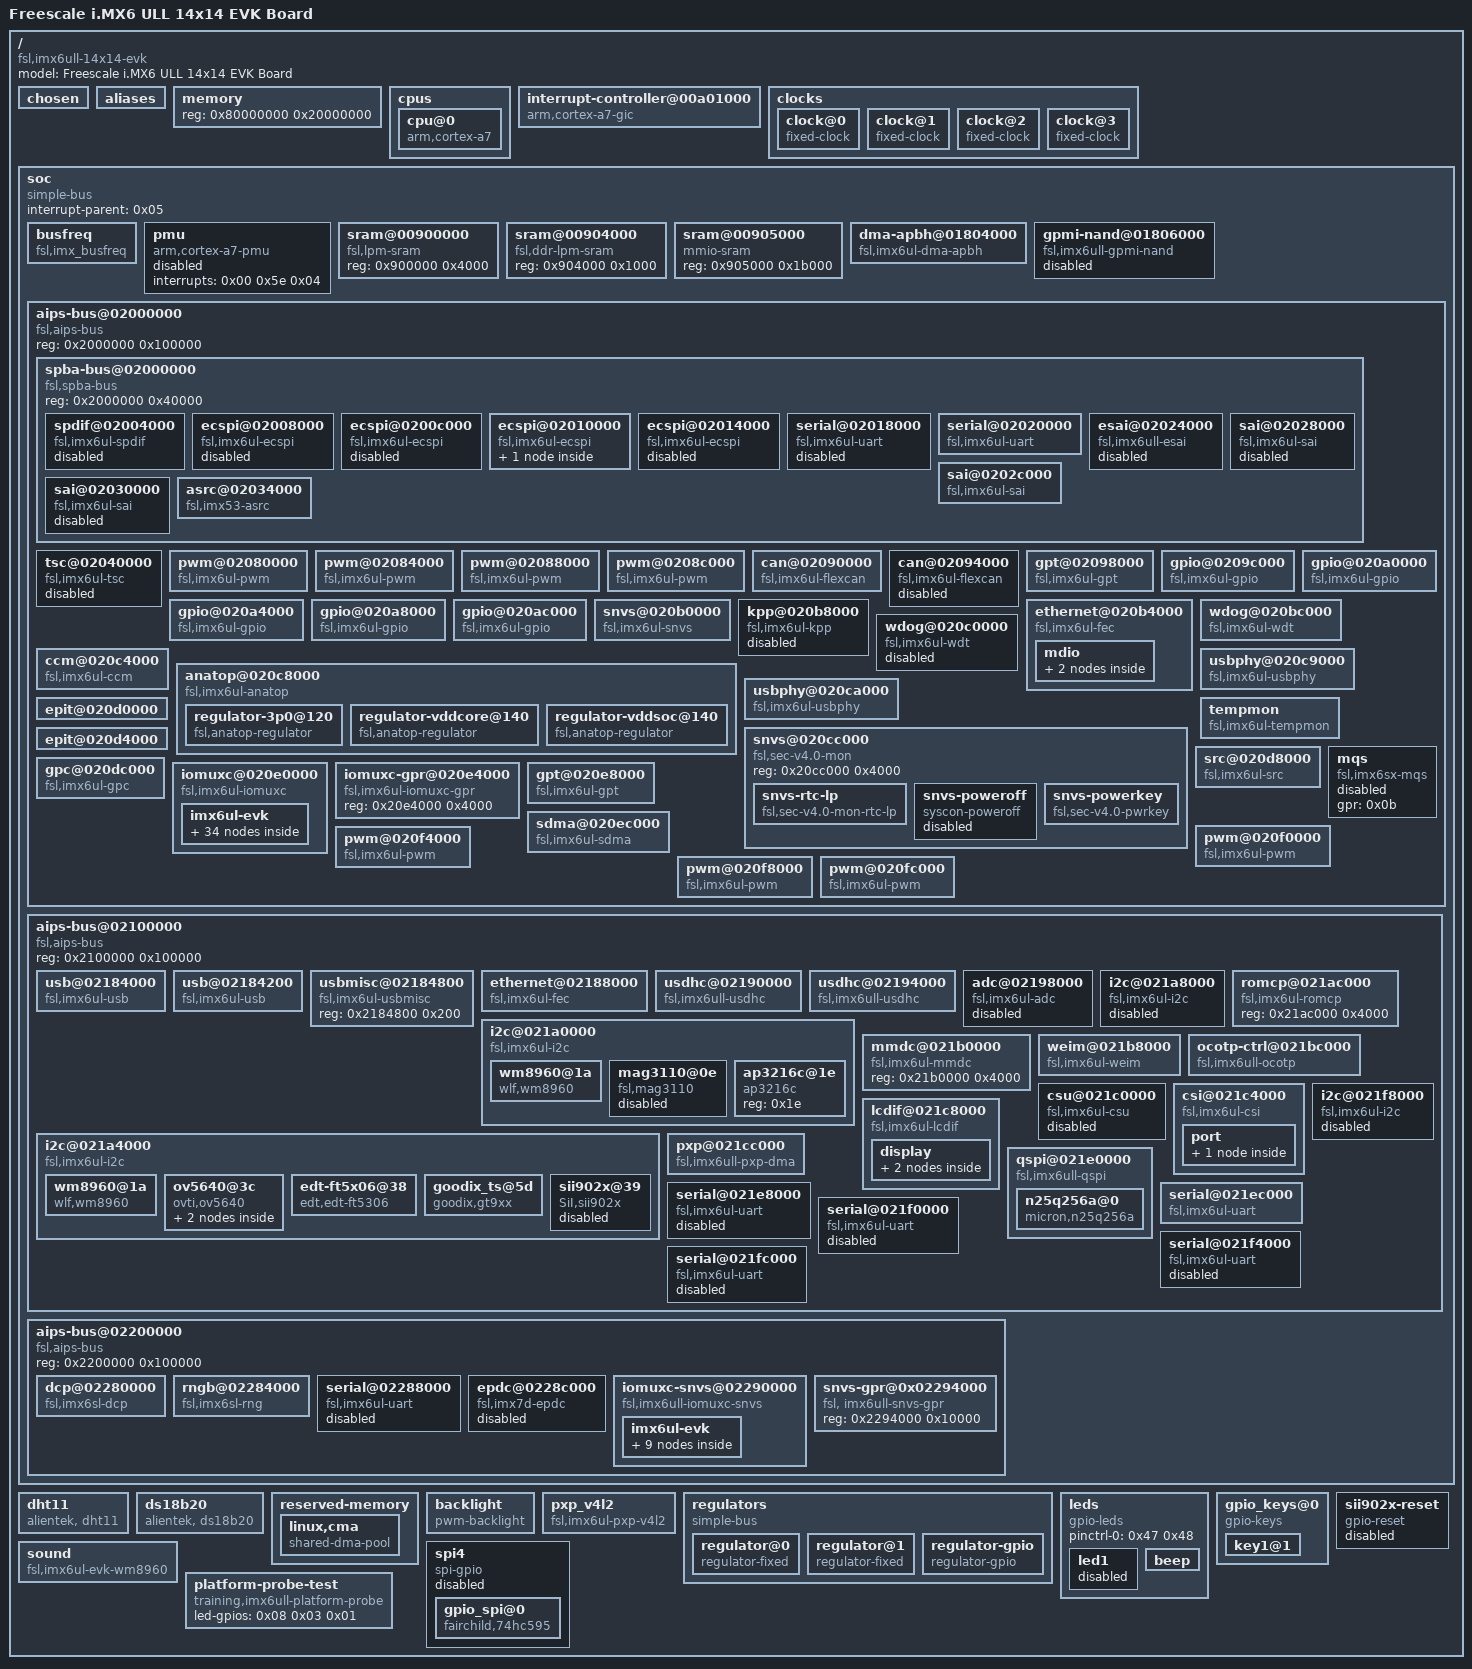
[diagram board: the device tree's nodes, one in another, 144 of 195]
/dts-v1/;

/memreserve/	0x0000000083000000 0x000000000000a000;
/ {
	#address-cells = <0x01>;
	#size-cells = <0x01>;
	model = "Freescale i.MX6 ULL 14x14 EVK Board";
	compatible = "fsl,imx6ull-14x14-evk\0fsl,imx6ull";

	chosen {
		bootargs = "console=ttymxc0,115200 root=/dev/mmcblk1p2 rootwait rw";
		stdout-path = "/soc/aips-bus@02000000/spba-bus@02000000/serial@02020000";
	};

	aliases {
		can0 = "/soc/aips-bus@02000000/can@02090000";
		can1 = "/soc/aips-bus@02000000/can@02094000";
		ethernet0 = "/soc/aips-bus@02100000/ethernet@02188000";
		ethernet1 = "/soc/aips-bus@02000000/ethernet@020b4000";
		gpio0 = "/soc/aips-bus@02000000/gpio@0209c000";
		gpio1 = "/soc/aips-bus@02000000/gpio@020a0000";
		gpio2 = "/soc/aips-bus@02000000/gpio@020a4000";
		gpio3 = "/soc/aips-bus@02000000/gpio@020a8000";
		gpio4 = "/soc/aips-bus@02000000/gpio@020ac000";
		i2c0 = "/soc/aips-bus@02100000/i2c@021a0000";
		i2c1 = "/soc/aips-bus@02100000/i2c@021a4000";
		i2c2 = "/soc/aips-bus@02100000/i2c@021a8000";
		i2c3 = "/soc/aips-bus@02100000/i2c@021f8000";
		mmc0 = "/soc/aips-bus@02100000/usdhc@02190000";
		mmc1 = "/soc/aips-bus@02100000/usdhc@02194000";
		serial0 = "/soc/aips-bus@02000000/spba-bus@02000000/serial@02020000";
		serial1 = "/soc/aips-bus@02100000/serial@021e8000";
		serial2 = "/soc/aips-bus@02100000/serial@021ec000";
		serial3 = "/soc/aips-bus@02100000/serial@021f0000";
		serial4 = "/soc/aips-bus@02100000/serial@021f4000";
		serial5 = "/soc/aips-bus@02100000/serial@021fc000";
		serial6 = "/soc/aips-bus@02000000/spba-bus@02000000/serial@02018000";
		serial7 = "/soc/aips-bus@02200000/serial@02288000";
		spi0 = "/soc/aips-bus@02000000/spba-bus@02000000/ecspi@02008000";
		spi1 = "/soc/aips-bus@02000000/spba-bus@02000000/ecspi@0200c000";
		spi2 = "/soc/aips-bus@02000000/spba-bus@02000000/ecspi@02010000";
		spi3 = "/soc/aips-bus@02000000/spba-bus@02000000/ecspi@02014000";
		usbphy0 = "/soc/aips-bus@02000000/usbphy@020c9000";
		usbphy1 = "/soc/aips-bus@02000000/usbphy@020ca000";
	};

	memory {
		device_type = "memory";
		reg = <0x80000000 0x20000000>;
	};

	cpus {
		#address-cells = <0x01>;
		#size-cells = <0x00>;

		cpu@0 {
			compatible = "arm,cortex-a7";
			device_type = "cpu";
			reg = <0x00>;
			clock-latency = <0xee6c>;
			operating-points = <0xf32a0 0x137478 0xc15c0 0x12b128 0x80e80 0x11edd8 0x60ae0 0xfa3e8 0x30570 0xe7ef0>;
			fsl,soc-operating-points = <0xf32a0 0x11edd8 0xc15c0 0x11edd8 0x80e80 0x11edd8 0x60ae0 0x11edd8 0x30570 0x11edd8>;
			fsl,low-power-run;
			clocks = <0x01 0x5d 0x01 0x1a 0x01 0x26 0x01 0xdb 0x01 0x38 0x01 0x39 0x01 0x19 0x01 0x12 0x01 0x0b 0x01 0x04 0x01 0x03>;
			clock-names = "arm\0pll2_bus\0pll2_pfd2_396m\0secondary_sel\0step\0pll1_sw\0pll1_sys\0pll1_bypass\0pll1\0pll1_bypass_src\0osc";
			arm-supply = <0x02>;
			soc-supply = <0x03>;
			dc-supply = <0x04>;
		};
	};

	interrupt-controller@00a01000 {
		compatible = "arm,cortex-a7-gic";
		#interrupt-cells = <0x03>;
		interrupt-controller;
		reg = <0xa01000 0x1000 0xa02000 0x100>;
		linux,phandle = <0x20>;
		phandle = <0x20>;
	};

	clocks {
		#address-cells = <0x01>;
		#size-cells = <0x00>;

		clock@0 {
			compatible = "fixed-clock";
			reg = <0x00>;
			#clock-cells = <0x00>;
			clock-frequency = <0x8000>;
			clock-output-names = "ckil";
			linux,phandle = <0x18>;
			phandle = <0x18>;
		};

		clock@1 {
			compatible = "fixed-clock";
			reg = <0x01>;
			#clock-cells = <0x00>;
			clock-frequency = <0x16e3600>;
			clock-output-names = "osc";
			linux,phandle = <0x19>;
			phandle = <0x19>;
		};

		clock@2 {
			compatible = "fixed-clock";
			reg = <0x02>;
			#clock-cells = <0x00>;
			clock-frequency = <0x00>;
			clock-output-names = "ipp_di0";
			linux,phandle = <0x1a>;
			phandle = <0x1a>;
		};

		clock@3 {
			compatible = "fixed-clock";
			reg = <0x03>;
			#clock-cells = <0x00>;
			clock-frequency = <0x00>;
			clock-output-names = "ipp_di1";
			linux,phandle = <0x1b>;
			phandle = <0x1b>;
		};
	};

	soc {
		#address-cells = <0x01>;
		#size-cells = <0x01>;
		compatible = "simple-bus";
		interrupt-parent = <0x05>;
		ranges;

		busfreq {
			compatible = "fsl,imx_busfreq";
			clocks = <0x01 0x26 0x01 0x35 0x01 0x1a 0x01 0x5d 0x01 0x1b 0x01 0x55 0x01 0x3c 0x01 0x5e 0x01 0x3e 0x01 0x03 0x01 0x60 0x01 0xd4 0x01 0x56 0x01 0x3d 0x01 0x5f 0x01 0x3f 0x01 0x38 0x01 0xa3 0x01 0x04 0x01 0x12 0x01 0x19 0x01 0x39 0x01 0x0b>;
			clock-names = "pll2_pfd2_396m\0pll2_198m\0pll2_bus\0arm\0pll3_usb_otg\0periph\0periph_pre\0periph_clk2\0periph_clk2_sel\0osc\0ahb\0ocram\0periph2\0periph2_pre\0periph2_clk2\0periph2_clk2_sel\0step\0mmdc\0pll1_bypass_src\0pll1_bypass\0pll1_sys\0pll1_sw\0pll1";
			fsl,max_ddr_freq = <0x17d78400>;
		};

		pmu {
			compatible = "arm,cortex-a7-pmu";
			interrupts = <0x00 0x5e 0x04>;
			status = "disabled";
		};

		sram@00900000 {
			compatible = "fsl,lpm-sram";
			reg = <0x900000 0x4000>;
		};

		sram@00904000 {
			compatible = "fsl,ddr-lpm-sram";
			reg = <0x904000 0x1000>;
		};

		sram@00905000 {
			compatible = "mmio-sram";
			reg = <0x905000 0x1b000>;
			linux,phandle = <0x22>;
			phandle = <0x22>;
		};

		dma-apbh@01804000 {
			compatible = "fsl,imx6ul-dma-apbh\0fsl,imx28-dma-apbh";
			reg = <0x1804000 0x2000>;
			interrupts = <0x00 0x0d 0x04 0x00 0x0d 0x04 0x00 0x0d 0x04 0x00 0x0d 0x04>;
			interrupt-names = "gpmi0\0gpmi1\0gpmi2\0gpmi3";
			#dma-cells = <0x01>;
			dma-channels = <0x04>;
			clocks = <0x01 0x80>;
			linux,phandle = <0x06>;
			phandle = <0x06>;
		};

		gpmi-nand@01806000 {
			compatible = "fsl,imx6ull-gpmi-nand\0fsl, imx6ul-gpmi-nand";
			#address-cells = <0x01>;
			#size-cells = <0x01>;
			reg = <0x1806000 0x2000 0x1808000 0x4000>;
			reg-names = "gpmi-nand\0bch";
			interrupts = <0x00 0x0f 0x04>;
			interrupt-names = "bch";
			clocks = <0x01 0x85 0x01 0x86 0x01 0x84 0x01 0x83 0x01 0xdc>;
			clock-names = "gpmi_io\0gpmi_apb\0gpmi_bch\0gpmi_bch_apb\0per1_bch";
			dmas = <0x06 0x00>;
			dma-names = "rx-tx";
			status = "disabled";
		};

		aips-bus@02000000 {
			compatible = "fsl,aips-bus\0simple-bus";
			#address-cells = <0x01>;
			#size-cells = <0x01>;
			reg = <0x2000000 0x100000>;
			ranges;

			spba-bus@02000000 {
				compatible = "fsl,spba-bus\0simple-bus";
				#address-cells = <0x01>;
				#size-cells = <0x01>;
				reg = <0x2000000 0x40000>;
				ranges;

				spdif@02004000 {
					compatible = "fsl,imx6ul-spdif\0fsl,imx35-spdif";
					reg = <0x2004000 0x4000>;
					interrupts = <0x00 0x34 0x04>;
					dmas = <0x07 0x29 0x12 0x00 0x07 0x2a 0x12 0x00>;
					dma-names = "rx\0tx";
					clocks = <0x01 0xd5 0x01 0x03 0x01 0xbc 0x01 0x00 0x01 0x00 0x01 0x00 0x01 0x64 0x01 0x00 0x01 0x00 0x01 0xbb>;
					clock-names = "core\0rxtx0\0rxtx1\0rxtx2\0rxtx3\0rxtx4\0rxtx5\0rxtx6\0rxtx7\0dma";
					status = "disabled";
				};

				ecspi@02008000 {
					#address-cells = <0x01>;
					#size-cells = <0x00>;
					compatible = "fsl,imx6ul-ecspi\0fsl,imx51-ecspi";
					reg = <0x2008000 0x4000>;
					interrupts = <0x00 0x1f 0x04>;
					clocks = <0x01 0x8b 0x01 0x8b>;
					clock-names = "ipg\0per";
					dmas = <0x07 0x03 0x07 0x01 0x07 0x04 0x07 0x02>;
					dma-names = "rx\0tx";
					status = "disabled";
				};

				ecspi@0200c000 {
					#address-cells = <0x01>;
					#size-cells = <0x00>;
					compatible = "fsl,imx6ul-ecspi\0fsl,imx51-ecspi";
					reg = <0x200c000 0x4000>;
					interrupts = <0x00 0x20 0x04>;
					clocks = <0x01 0x8c 0x01 0x8c>;
					clock-names = "ipg\0per";
					dmas = <0x07 0x05 0x07 0x01 0x07 0x06 0x07 0x02>;
					dma-names = "rx\0tx";
					status = "disabled";
				};

				ecspi@02010000 {
					#address-cells = <0x01>;
					#size-cells = <0x00>;
					compatible = "fsl,imx6ul-ecspi\0fsl,imx51-ecspi";
					reg = <0x2010000 0x4000>;
					interrupts = <0x00 0x21 0x04>;
					clocks = <0x01 0x8d 0x01 0x8d>;
					clock-names = "ipg\0per";
					dmas = <0x07 0x07 0x07 0x01 0x07 0x08 0x07 0x02>;
					dma-names = "rx\0tx";
					status = "okay";
					fsl,spi-num-chipselects = <0x01>;
					cs-gpio = <0x08 0x14 0x01>;
					pinctrl-names = "default";
					pinctrl-0 = <0x09>;

					icm20608@0 {
						compatible = "alientek,icm20608";
						spi-max-frequency = <0x7a1200>;
						reg = <0x00>;
					};
				};

				ecspi@02014000 {
					#address-cells = <0x01>;
					#size-cells = <0x00>;
					compatible = "fsl,imx6ul-ecspi\0fsl,imx51-ecspi";
					reg = <0x2014000 0x4000>;
					interrupts = <0x00 0x22 0x04>;
					clocks = <0x01 0x8e 0x01 0x8e>;
					clock-names = "ipg\0per";
					dmas = <0x07 0x09 0x07 0x01 0x07 0x0a 0x07 0x02>;
					dma-names = "rx\0tx";
					status = "disabled";
				};

				serial@02018000 {
					compatible = "fsl,imx6ul-uart\0fsl,imx6q-uart\0fsl,imx21-uart";
					reg = <0x2018000 0x4000>;
					interrupts = <0x00 0x27 0x04>;
					clocks = <0x01 0xc9 0x01 0xca>;
					clock-names = "ipg\0per";
					dmas = <0x07 0x2b 0x04 0x00 0x07 0x2c 0x04 0x00>;
					dma-names = "rx\0tx";
					status = "disabled";
				};

				serial@02020000 {
					compatible = "fsl,imx6ul-uart\0fsl,imx6q-uart\0fsl,imx21-uart";
					reg = <0x2020000 0x4000>;
					interrupts = <0x00 0x1a 0x04>;
					clocks = <0x01 0xbd 0x01 0xbe>;
					clock-names = "ipg\0per";
					status = "okay";
					pinctrl-names = "default";
					pinctrl-0 = <0x0a>;
				};

				esai@02024000 {
					compatible = "fsl,imx6ull-esai";
					reg = <0x2024000 0x4000>;
					interrupts = <0x00 0x33 0x04>;
					clocks = <0x01 0xe5 0x01 0xe4 0x01 0xe3 0x01 0xe5 0x01 0xbb>;
					clock-names = "core\0mem\0extal\0fsys\0dma";
					dmas = <0x07 0x00 0x15 0x00 0x07 0x2f 0x15 0x00>;
					dma-names = "rx\0tx";
					dma-source = <0x0b 0x00 0x0e 0x00 0x0f>;
					status = "disabled";
				};

				sai@02028000 {
					compatible = "fsl,imx6ul-sai\0fsl,imx6sx-sai";
					reg = <0x2028000 0x4000>;
					interrupts = <0x00 0x61 0x04>;
					clocks = <0x01 0xb3 0x01 0x00 0x01 0xb2 0x01 0x00 0x01 0x00>;
					clock-names = "bus\0mclk0\0mclk1\0mclk2\0mclk3";
					dma-names = "rx\0tx";
					dmas = <0x07 0x23 0x18 0x00 0x07 0x24 0x18 0x00>;
					status = "disabled";
				};

				sai@0202c000 {
					compatible = "fsl,imx6ul-sai\0fsl,imx6sx-sai";
					reg = <0x202c000 0x4000>;
					interrupts = <0x00 0x62 0x04>;
					clocks = <0x01 0xb5 0x01 0x00 0x01 0xb4 0x01 0x00 0x01 0x00>;
					clock-names = "bus\0mclk0\0mclk1\0mclk2\0mclk3";
					dma-names = "rx\0tx";
					dmas = <0x07 0x25 0x18 0x00 0x07 0x26 0x18 0x00>;
					status = "okay";
					pinctrl-names = "default";
					pinctrl-0 = <0x0c 0x0d>;
					assigned-clocks = <0x01 0x47 0x01 0xb4>;
					assigned-clock-parents = <0x01 0x32>;
					assigned-clock-rates = <0x00 0xac4400>;
					linux,phandle = <0x4a>;
					phandle = <0x4a>;
				};

				sai@02030000 {
					compatible = "fsl,imx6ul-sai\0fsl,imx6sx-sai";
					reg = <0x2030000 0x4000>;
					interrupts = <0x00 0x18 0x04>;
					clocks = <0x01 0xb7 0x01 0x00 0x01 0xb6 0x01 0x00 0x01 0x00>;
					clock-names = "bus\0mclk0\0mclk1\0mclk2\0mclk3";
					dma-names = "rx\0tx";
					dmas = <0x07 0x27 0x18 0x00 0x07 0x28 0x18 0x00>;
					status = "disabled";
				};

				asrc@02034000 {
					compatible = "fsl,imx53-asrc";
					reg = <0x2034000 0x4000>;
					interrupts = <0x00 0x32 0x04>;
					clocks = <0x01 0x81 0x01 0x82 0x01 0x00 0x01 0x00 0x01 0x00 0x01 0x00 0x01 0x00 0x01 0x00 0x01 0x00 0x01 0x00 0x01 0x00 0x01 0x00 0x01 0x00 0x01 0x00 0x01 0x00 0x01 0xbc 0x01 0x00 0x01 0x00 0x01 0xbb>;
					clock-names = "mem\0ipg\0asrck_0\0asrck_1\0asrck_2\0asrck_3\0asrck_4\0asrck_5\0asrck_6\0asrck_7\0asrck_8\0asrck_9\0asrck_a\0asrck_b\0asrck_c\0asrck_d\0asrck_e\0asrck_f\0dma";
					dmas = <0x07 0x11 0x17 0x01 0x07 0x12 0x17 0x01 0x07 0x13 0x17 0x01 0x07 0x14 0x17 0x01 0x07 0x15 0x17 0x01 0x07 0x16 0x17 0x01>;
					dma-names = "rxa\0rxb\0rxc\0txa\0txb\0txc";
					fsl,asrc-rate = <0xbb80>;
					fsl,asrc-width = <0x10>;
					status = "okay";
					linux,phandle = <0x4d>;
					phandle = <0x4d>;
				};
			};

			tsc@02040000 {
				compatible = "fsl,imx6ul-tsc";
				reg = <0x2040000 0x4000 0x219c000 0x4000>;
				interrupts = <0x00 0x03 0x04 0x00 0x65 0x04>;
				clocks = <0x01 0x64 0x01 0x7c>;
				clock-names = "tsc\0adc";
				status = "disabled";
				pinctrl-names = "default";
				pinctrl-0 = <0x0e>;
				xnur-gpio = <0x08 0x03 0x01>;
				measure-delay-time = <0xffff>;
				pre-charge-time = <0xfff>;
			};

			pwm@02080000 {
				compatible = "fsl,imx6ul-pwm\0fsl,imx27-pwm";
				reg = <0x2080000 0x4000>;
				interrupts = <0x00 0x53 0x04>;
				clocks = <0x01 0xa7 0x01 0xa7>;
				clock-names = "ipg\0per";
				#pwm-cells = <0x02>;
				pinctrl-names = "default";
				pinctrl-0 = <0x0f>;
				status = "okay";
				linux,phandle = <0x44>;
				phandle = <0x44>;
			};

			pwm@02084000 {
				compatible = "fsl,imx6ul-pwm\0fsl,imx27-pwm";
				reg = <0x2084000 0x4000>;
				interrupts = <0x00 0x54 0x04>;
				clocks = <0x01 0x00 0x01 0x00>;
				clock-names = "ipg\0per";
				#pwm-cells = <0x02>;
			};

			pwm@02088000 {
				compatible = "fsl,imx6ul-pwm\0fsl,imx27-pwm";
				reg = <0x2088000 0x4000>;
				interrupts = <0x00 0x55 0x04>;
				clocks = <0x01 0xa9 0x01 0xa9>;
				clock-names = "ipg\0per";
				#pwm-cells = <0x02>;
			};

			pwm@0208c000 {
				compatible = "fsl,imx6ul-pwm\0fsl,imx27-pwm";
				reg = <0x208c000 0x4000>;
				interrupts = <0x00 0x56 0x04>;
				clocks = <0x01 0x00 0x01 0x00>;
				clock-names = "ipg\0per";
				#pwm-cells = <0x02>;
			};

			can@02090000 {
				compatible = "fsl,imx6ul-flexcan\0fsl,imx6q-flexcan";
				reg = <0x2090000 0x4000>;
				interrupts = <0x00 0x6e 0x04>;
				clocks = <0x01 0x94 0x01 0x95>;
				clock-names = "ipg\0per";
				stop-mode = <0x0b 0x10 0x01 0x10 0x11>;
				status = "okay";
				pinctrl-names = "default";
				pinctrl-0 = <0x10>;
				xceiver-supply = <0x11>;
			};

			can@02094000 {
				compatible = "fsl,imx6ul-flexcan\0fsl,imx6q-flexcan";
				reg = <0x2094000 0x4000>;
				interrupts = <0x00 0x6f 0x04>;
				clocks = <0x01 0x96 0x01 0x97>;
				clock-names = "ipg\0per";
				stop-mode = <0x0b 0x10 0x02 0x10 0x12>;
				status = "disabled";
				pinctrl-names = "default";
				pinctrl-0 = <0x12>;
				xceiver-supply = <0x11>;
			};

			gpt@02098000 {
				compatible = "fsl,imx6ul-gpt\0fsl,imx31-gpt";
				reg = <0x2098000 0x4000>;
				interrupts = <0x00 0x37 0x04>;
				clocks = <0x01 0x98 0x01 0xd6>;
				clock-names = "ipg\0osc_per";
			};

			gpio@0209c000 {
				compatible = "fsl,imx6ul-gpio\0fsl,imx35-gpio";
				reg = <0x209c000 0x4000>;
				interrupts = <0x00 0x42 0x04 0x00 0x43 0x04>;
				gpio-controller;
				#gpio-cells = <0x02>;
				interrupt-controller;
				#interrupt-cells = <0x02>;
				linux,phandle = <0x08>;
				phandle = <0x08>;
			};

			gpio@020a0000 {
				compatible = "fsl,imx6ul-gpio\0fsl,imx35-gpio";
				reg = <0x20a0000 0x4000>;
				interrupts = <0x00 0x44 0x04 0x00 0x45 0x04>;
				gpio-controller;
				#gpio-cells = <0x02>;
				interrupt-controller;
				#interrupt-cells = <0x02>;
			};

			gpio@020a4000 {
				compatible = "fsl,imx6ul-gpio\0fsl,imx35-gpio";
				reg = <0x20a4000 0x4000>;
				interrupts = <0x00 0x46 0x04 0x00 0x47 0x04>;
				gpio-controller;
				#gpio-cells = <0x02>;
				interrupt-controller;
				#interrupt-cells = <0x02>;
			};

			gpio@020a8000 {
				compatible = "fsl,imx6ul-gpio\0fsl,imx35-gpio";
				reg = <0x20a8000 0x4000>;
				interrupts = <0x00 0x48 0x04 0x00 0x49 0x04>;
				gpio-controller;
				#gpio-cells = <0x02>;
				interrupt-controller;
				#interrupt-cells = <0x02>;
			};

			gpio@020ac000 {
				compatible = "fsl,imx6ul-gpio\0fsl,imx35-gpio";
				reg = <0x20ac000 0x4000>;
				interrupts = <0x00 0x4a 0x04 0x00 0x4b 0x04>;
				gpio-controller;
				#gpio-cells = <0x02>;
				interrupt-controller;
				#interrupt-cells = <0x02>;
				linux,phandle = <0x16>;
				phandle = <0x16>;
			};

			snvs@020b0000 {
				compatible = "fsl,imx6ul-snvs";
				reg = <0x20b0000 0x4000>;
				interrupts = <0x00 0x04 0x04>;
			};

			ethernet@020b4000 {
				compatible = "fsl,imx6ul-fec\0fsl,imx6q-fec";
				reg = <0x20b4000 0x4000>;
				interrupts = <0x00 0x78 0x04 0x00 0x79 0x04>;
				clocks = <0x01 0x90 0x01 0x91 0x01 0x30 0x01 0x2e 0x01 0x2e>;
				clock-names = "ipg\0ahb\0ptp\0enet_clk_ref\0enet_out";
				stop-mode = <0x0b 0x10 0x04>;
				fsl,num-tx-queues = <0x01>;
				fsl,num-rx-queues = <0x01>;
				fsl,magic-packet;
				fsl,wakeup_irq = <0x00>;
				status = "okay";
				pinctrl-names = "default";
				pinctrl-0 = <0x13 0x14>;
				phy-mode = "rmii";
				phy-handle = <0x15>;
				phy-reset-gpios = <0x16 0x08 0x01>;
				phy-reset-duration = <0xc8>;

				mdio {
					#address-cells = <0x01>;
					#size-cells = <0x00>;

					ethernet-phy@2 {
						compatible = "ethernet-phy-ieee802.3-c22";
						reg = <0x02>;
						linux,phandle = <0x28>;
						phandle = <0x28>;
					};

					ethernet-phy@1 {
						compatible = "ethernet-phy-ieee802.3-c22";
						reg = <0x01>;
						linux,phandle = <0x15>;
						phandle = <0x15>;
					};
				};
			};

			kpp@020b8000 {
				compatible = "fsl,imx6ul-kpp\0fsl,imx21-kpp";
				reg = <0x20b8000 0x4000>;
				interrupts = <0x00 0x52 0x04>;
				clocks = <0x01 0x00>;
				status = "disabled";
			};

			wdog@020bc000 {
				compatible = "fsl,imx6ul-wdt\0fsl,imx21-wdt";
				reg = <0x20bc000 0x4000>;
				interrupts = <0x00 0x50 0x04>;
				clocks = <0x01 0xd0>;
				pinctrl-names = "default";
				pinctrl-0 = <0x17>;
				fsl,wdog_b;
			};

			wdog@020c0000 {
				compatible = "fsl,imx6ul-wdt\0fsl,imx21-wdt";
				reg = <0x20c0000 0x4000>;
				interrupts = <0x00 0x51 0x04>;
				clocks = <0x01 0xd1>;
				status = "disabled";
			};

			ccm@020c4000 {
				compatible = "fsl,imx6ul-ccm";
				reg = <0x20c4000 0x4000>;
				interrupts = <0x00 0x57 0x04 0x00 0x58 0x04>;
				#clock-cells = <0x01>;
				clocks = <0x18 0x19 0x1a 0x1b>;
				clock-names = "ckil\0osc\0ipp_di0\0ipp_di1";
				assigned-clocks = <0x01 0x32>;
				assigned-clock-rates = <0x2b110000>;
				linux,phandle = <0x01>;
				phandle = <0x01>;
			};

			anatop@020c8000 {
				compatible = "fsl,imx6ul-anatop\0fsl,imx6q-anatop\0syscon\0simple-bus";
				reg = <0x20c8000 0x1000>;
				interrupts = <0x00 0x31 0x04 0x00 0x36 0x04 0x00 0x7f 0x04>;
				linux,phandle = <0x1d>;
				phandle = <0x1d>;

				regulator-3p0@120 {
					compatible = "fsl,anatop-regulator";
					regulator-name = "vdd3p0";
					regulator-min-microvolt = <0x280de8>;
					regulator-max-microvolt = <0x33e140>;
					anatop-reg-offset = <0x120>;
					anatop-vol-bit-shift = <0x08>;
					anatop-vol-bit-width = <0x05>;
					anatop-min-bit-val = <0x00>;
					anatop-min-voltage = <0x280de8>;
					anatop-max-voltage = <0x33e140>;
					anatop-enable-bit = <0x00>;
					linux,phandle = <0x1c>;
					phandle = <0x1c>;
				};

				regulator-vddcore@140 {
					compatible = "fsl,anatop-regulator";
					regulator-name = "cpu";
					regulator-min-microvolt = <0xb1008>;
					regulator-max-microvolt = <0x162010>;
					regulator-always-on;
					anatop-reg-offset = <0x140>;
					anatop-vol-bit-shift = <0x00>;
					anatop-vol-bit-width = <0x05>;
					anatop-delay-reg-offset = <0x170>;
					anatop-delay-bit-shift = <0x18>;
					anatop-delay-bit-width = <0x02>;
					anatop-min-bit-val = <0x01>;
					anatop-min-voltage = <0xb1008>;
					anatop-max-voltage = <0x162010>;
					linux,phandle = <0x02>;
					phandle = <0x02>;
				};

				regulator-vddsoc@140 {
					compatible = "fsl,anatop-regulator";
					regulator-name = "vddsoc";
					regulator-min-microvolt = <0xb1008>;
					regulator-max-microvolt = <0x162010>;
					regulator-always-on;
					anatop-reg-offset = <0x140>;
					anatop-vol-bit-shift = <0x12>;
					anatop-vol-bit-width = <0x05>;
					anatop-delay-reg-offset = <0x170>;
					anatop-delay-bit-shift = <0x1c>;
					anatop-delay-bit-width = <0x02>;
					anatop-min-bit-val = <0x01>;
					anatop-min-voltage = <0xb1008>;
					anatop-max-voltage = <0x162010>;
					linux,phandle = <0x03>;
					phandle = <0x03>;
				};
			};

			usbphy@020c9000 {
				compatible = "fsl,imx6ul-usbphy\0fsl,imx23-usbphy";
				reg = <0x20c9000 0x1000>;
				interrupts = <0x00 0x2c 0x04>;
				clocks = <0x01 0x20>;
				phy-3p0-supply = <0x1c>;
				fsl,anatop = <0x1d>;
				tx-d-cal = <0x05>;
				linux,phandle = <0x23>;
				phandle = <0x23>;
			};

			usbphy@020ca000 {
				compatible = "fsl,imx6ul-usbphy\0fsl,imx23-usbphy";
				reg = <0x20ca000 0x1000>;
				interrupts = <0x00 0x2d 0x04>;
				clocks = <0x01 0x21>;
				phy-3p0-supply = <0x1c>;
				fsl,anatop = <0x1d>;
				tx-d-cal = <0x05>;
				linux,phandle = <0x25>;
				phandle = <0x25>;
			};

			tempmon {
				compatible = "fsl,imx6ul-tempmon\0fsl,imx6sx-tempmon";
				interrupts = <0x00 0x31 0x04>;
				fsl,tempmon = <0x1d>;
				fsl,tempmon-data = <0x1e>;
				clocks = <0x01 0x1b>;
			};

			snvs@020cc000 {
				compatible = "fsl,sec-v4.0-mon\0syscon\0simple-mfd";
				reg = <0x20cc000 0x4000>;
				linux,phandle = <0x1f>;
				phandle = <0x1f>;

				snvs-rtc-lp {
					compatible = "fsl,sec-v4.0-mon-rtc-lp";
					regmap = <0x1f>;
					offset = <0x34>;
					interrupts = <0x00 0x13 0x04 0x00 0x14 0x04>;
				};

				snvs-poweroff {
					compatible = "syscon-poweroff";
					regmap = <0x1f>;
					offset = <0x38>;
					mask = <0x61>;
					status = "disabled";
				};

				snvs-powerkey {
					compatible = "fsl,sec-v4.0-pwrkey";
					regmap = <0x1f>;
					interrupts = <0x00 0x04 0x04>;
					linux,keycode = <0x74>;
					wakeup;
				};
			};

			epit@020d0000 {
				reg = <0x20d0000 0x4000>;
				interrupts = <0x00 0x38 0x04>;
			};

			epit@020d4000 {
				reg = <0x20d4000 0x4000>;
				interrupts = <0x00 0x39 0x04>;
			};

			src@020d8000 {
				compatible = "fsl,imx6ul-src\0fsl,imx51-src";
				reg = <0x20d8000 0x4000>;
				interrupts = <0x00 0x5b 0x04 0x00 0x60 0x04>;
				#reset-cells = <0x01>;
			};

			gpc@020dc000 {
				compatible = "fsl,imx6ul-gpc\0fsl,imx6q-gpc";
				reg = <0x20dc000 0x4000>;
				interrupt-controller;
				#interrupt-cells = <0x03>;
				interrupts = <0x00 0x59 0x04>;
				interrupt-parent = <0x20>;
				fsl,mf-mix-wakeup-irq = <0xfc00000 0x7d00 0x00 0x1400640>;
				fsl,cpu_pupscr_sw2iso = <0x01>;
				fsl,cpu_pupscr_sw = <0x00>;
				fsl,cpu_pdnscr_iso2sw = <0x01>;
				fsl,cpu_pdnscr_iso = <0x01>;
				fsl,ldo-bypass = <0x00>;
				linux,phandle = <0x05>;
				phandle = <0x05>;
			};

			iomuxc@020e0000 {
				compatible = "fsl,imx6ul-iomuxc";
				reg = <0x20e0000 0x4000>;
				pinctrl-names = "default";
				pinctrl-0 = <0x21>;

				imx6ul-evk {

					hoggrp-1 {
						fsl,pins = <0x90 0x31c 0x00 0x05 0x00 0x17059 0x70 0x2fc 0x00 0x04 0x00 0x17059 0x5c 0x2e8 0x4b8 0x02 0x00 0x13058>;
						linux,phandle = <0x21>;
						phandle = <0x21>;
					};

					csi1grp {
						fsl,pins = <0x1d4 0x460 0x00 0x00 0x00 0x1b088 0x1d8 0x464 0x528 0x00 0x01 0x1b088 0x1dc 0x468 0x52c 0x00 0x00 0x1b088 0x1e0 0x46c 0x524 0x00 0x00 0x1b088 0x1e4 0x470 0x4c4 0x00 0x00 0x1b088 0x1e8 0x474 0x4c8 0x00 0x00 0x1b088 0x1ec 0x478 0x4d8 0x00 0x01 0x1b088 0x1f0 0x47c 0x4cc 0x00 0x00 0x1b088 0x1f4 0x480 0x4dc 0x00 0x01 0x1b088 0x1f8 0x484 0x4e0 0x00 0x01 0x1b088 0x1fc 0x488 0x4e4 0x00 0x01 0x1b088 0x200 0x48c 0x4e8 0x00 0x01 0x1b088>;
						linux,phandle = <0x32>;
						phandle = <0x32>;
					};

					18b20 {
						fsl,pins = <0x60 0x2ec 0x00 0x05 0x00 0x17059>;
						linux,phandle = <0x43>;
						phandle = <0x43>;
					};

					dht11 {
						fsl,pins = <0x60 0x2ec 0x00 0x05 0x00 0x17059>;
						linux,phandle = <0x42>;
						phandle = <0x42>;
					};

					enet1grp {
						fsl,pins = <0xcc 0x358 0x00 0x00 0x00 0x1b0b0 0xe0 0x36c 0x00 0x00 0x00 0x1b0b0 0xc4 0x350 0x00 0x00 0x00 0x1b0b0 0xc8 0x354 0x00 0x00 0x00 0x1b0b0 0xd8 0x364 0x00 0x00 0x00 0x1b0b0 0xd0 0x35c 0x00 0x00 0x00 0x1b0b0 0xd4 0x360 0x00 0x00 0x00 0x1b0b0 0xdc 0x368 0x574 0x04 0x02 0x4001b009>;
						linux,phandle = <0x26>;
						phandle = <0x26>;
					};

					enet2grp {
						fsl,pins = <0x78 0x304 0x00 0x01 0x00 0x1b0b0 0x74 0x300 0x580 0x01 0x00 0x1b0b0 0xec 0x378 0x00 0x00 0x00 0x1b0b0 0x100 0x38c 0x00 0x00 0x00 0x1b0b0 0xe4 0x370 0x00 0x00 0x00 0x1b0b0 0xe8 0x374 0x00 0x00 0x00 0x1b0b0 0xf8 0x384 0x00 0x00 0x00 0x1b0b0 0xf0 0x37c 0x00 0x00 0x00 0x1b0b0 0xf4 0x380 0x00 0x00 0x00 0x1b0b0 0xfc 0x388 0x57c 0x04 0x02 0x4001b009>;
						linux,phandle = <0x13>;
						phandle = <0x13>;
					};

					ecspi3grp {
						fsl,pins = <0xa0 0x32c 0x558 0x08 0x00 0x100b1 0x9c 0x328 0x55c 0x08 0x00 0x100b1 0x98 0x324 0x554 0x08 0x00 0x100b1 0x94 0x320 0x00 0x05 0x00 0x100b0>;
						linux,phandle = <0x09>;
						phandle = <0x09>;
					};

					gpio-leds {
						fsl,pins = <0x68 0x2f4 0x00 0x05 0x00 0x17059>;
						linux,phandle = <0x47>;
						phandle = <0x47>;
					};

					gpio-keys {
						fsl,pins = <0x8c 0x318 0x00 0x05 0x00 0x80000000>;
						linux,phandle = <0x49>;
						phandle = <0x49>;
					};

					flexcan1grp {
						fsl,pins = <0xb0 0x33c 0x584 0x02 0x00 0x1b020 0xac 0x338 0x00 0x02 0x00 0x1b020>;
						linux,phandle = <0x10>;
						phandle = <0x10>;
					};

					flexcan2grp {
						fsl,pins = <0xa0 0x32c 0x588 0x02 0x00 0x1b020 0x9c 0x328 0x00 0x02 0x00 0x1b020>;
						linux,phandle = <0x12>;
						phandle = <0x12>;
					};

					i2c1grp {
						fsl,pins = <0xb4 0x340 0x5a4 0x02 0x01 0x4001b8b0 0xb8 0x344 0x5a8 0x02 0x02 0x4001b8b0>;
						linux,phandle = <0x30>;
						phandle = <0x30>;
					};

					i2c2grp {
						fsl,pins = <0xbc 0x348 0x5ac 0x02 0x02 0x4001b8b0 0xc0 0x34c 0x5b0 0x02 0x02 0x4001b8b0>;
						linux,phandle = <0x31>;
						phandle = <0x31>;
					};

					lcdifdatgrp {
						fsl,pins = <0x118 0x3a4 0x00 0x00 0x00 0x79 0x11c 0x3a8 0x00 0x00 0x00 0x79 0x120 0x3ac 0x00 0x00 0x00 0x79 0x124 0x3b0 0x00 0x00 0x00 0x79 0x128 0x3b4 0x00 0x00 0x00 0x79 0x12c 0x3b8 0x00 0x00 0x00 0x79 0x130 0x3bc 0x00 0x00 0x00 0x79 0x134 0x3c0 0x00 0x00 0x00 0x79 0x138 0x3c4 0x00 0x00 0x00 0x79 0x13c 0x3c8 0x00 0x00 0x00 0x79 0x140 0x3cc 0x00 0x00 0x00 0x79 0x144 0x3d0 0x00 0x00 0x00 0x79 0x148 0x3d4 0x00 0x00 0x00 0x79 0x14c 0x3d8 0x00 0x00 0x00 0x79 0x150 0x3dc 0x00 0x00 0x00 0x79 0x154 0x3e0 0x00 0x00 0x00 0x79 0x158 0x3e4 0x00 0x00 0x00 0x79 0x15c 0x3e8 0x00 0x00 0x00 0x79 0x160 0x3ec 0x00 0x00 0x00 0x79 0x164 0x3f0 0x00 0x00 0x00 0x79 0x168 0x3f4 0x00 0x00 0x00 0x79 0x16c 0x3f8 0x00 0x00 0x00 0x79 0x170 0x3fc 0x00 0x00 0x00 0x79 0x174 0x400 0x00 0x00 0x00 0x79>;
						linux,phandle = <0x3a>;
						phandle = <0x3a>;
					};

					lcdifctrlgrp {
						fsl,pins = <0x104 0x390 0x00 0x00 0x00 0x79 0x108 0x394 0x00 0x00 0x00 0x79 0x10c 0x398 0x5dc 0x00 0x00 0x79 0x110 0x39c 0x00 0x00 0x00 0x79>;
						linux,phandle = <0x3b>;
						phandle = <0x3b>;
					};

					pwm1grp {
						fsl,pins = <0x7c 0x308 0x00 0x00 0x00 0x110b0>;
						linux,phandle = <0x0f>;
						phandle = <0x0f>;
					};

					qspigrp {
						fsl,pins = <0x1a4 0x430 0x00 0x02 0x00 0x70a1 0x1a8 0x434 0x00 0x02 0x00 0x70a1 0x1ac 0x438 0x00 0x02 0x00 0x70a1 0x1b0 0x43c 0x00 0x02 0x00 0x70a1 0x1b4 0x440 0x00 0x02 0x00 0x70a1 0x1b8 0x444 0x00 0x02 0x00 0x70a1>;
						linux,phandle = <0x3e>;
						phandle = <0x3e>;
					};

					sai2grp {
						fsl,pins = <0x50 0x2dc 0x5f8 0x02 0x00 0x17088 0x4c 0x2d8 0x5fc 0x02 0x00 0x17088 0x58 0x2e4 0x00 0x02 0x00 0x11088 0x54 0x2e0 0x5f4 0x02 0x00 0x11088 0x48 0x2d4 0x5f0 0x02 0x00 0x17088>;
						linux,phandle = <0x0c>;
						phandle = <0x0c>;
					};

					hdmigrp-1 {
						fsl,pins = <0x80 0x30c 0x00 0x05 0x00 0x11>;
						linux,phandle = <0x37>;
						phandle = <0x37>;
					};

					tscgrp {
						fsl,pins = <0x60 0x2ec 0x00 0x05 0x00 0xb0 0x64 0x2f0 0x00 0x05 0x00 0xb0 0x68 0x2f4 0x00 0x05 0x00 0xb0 0x6c 0x2f8 0x00 0x05 0x00 0xb0>;
						linux,phandle = <0x0e>;
						phandle = <0x0e>;
					};

					uart1grp {
						fsl,pins = <0x84 0x310 0x00 0x00 0x00 0x1b0b1 0x88 0x314 0x624 0x00 0x03 0x1b0b1>;
						linux,phandle = <0x0a>;
						phandle = <0x0a>;
					};

					uart2grp {
						fsl,pins = <0x94 0x320 0x00 0x00 0x00 0x1b0b1 0x98 0x324 0x62c 0x00 0x01 0x1b0b1 0xa8 0x334 0x628 0x04 0x03 0x1b0b1 0xa4 0x330 0x00 0x04 0x00 0x1b0b1>;
						linux,phandle = <0x3f>;
						phandle = <0x3f>;
					};

					uart2dtegrp {
						fsl,pins = <0x94 0x320 0x62c 0x00 0x00 0x1b0b1 0x98 0x324 0x00 0x00 0x00 0x1b0b1 0xa8 0x334 0x00 0x04 0x00 0x1b0b1 0xa4 0x330 0x628 0x04 0x02 0x1b0b1>;
					};

					uart3grp {
						fsl,pins = <0xa8 0x334 0x634 0x00 0x01 0x1b0b1 0xa4 0x330 0x00 0x00 0x00 0x1b0b1>;
						linux,phandle = <0x40>;
						phandle = <0x40>;
					};

					usdhc1grp {
						fsl,pins = <0x1bc 0x448 0x00 0x00 0x00 0x17059 0x1c0 0x44c 0x00 0x00 0x00 0x10071 0x1c4 0x450 0x00 0x00 0x00 0x17059 0x1c8 0x454 0x00 0x00 0x00 0x17059 0x1cc 0x458 0x00 0x00 0x00 0x17059 0x1d0 0x45c 0x00 0x00 0x00 0x17059>;
						linux,phandle = <0x29>;
						phandle = <0x29>;
					};

					usdhc1grp100mhz {
						fsl,pins = <0x1bc 0x448 0x00 0x00 0x00 0x170b9 0x1c0 0x44c 0x00 0x00 0x00 0x100b9 0x1c4 0x450 0x00 0x00 0x00 0x170b9 0x1c8 0x454 0x00 0x00 0x00 0x170b9 0x1cc 0x458 0x00 0x00 0x00 0x170b9 0x1d0 0x45c 0x00 0x00 0x00 0x170b9>;
						linux,phandle = <0x2a>;
						phandle = <0x2a>;
					};

					usdhc1grp200mhz {
						fsl,pins = <0x1bc 0x448 0x00 0x00 0x00 0x170f9 0x1c0 0x44c 0x00 0x00 0x00 0x100f9 0x1c4 0x450 0x00 0x00 0x00 0x170f9 0x1c8 0x454 0x00 0x00 0x00 0x170f9 0x1cc 0x458 0x00 0x00 0x00 0x170f9 0x1d0 0x45c 0x00 0x00 0x00 0x170f9>;
						linux,phandle = <0x2b>;
						phandle = <0x2b>;
					};

					usdhc2grp {
						fsl,pins = <0x178 0x404 0x670 0x01 0x02 0x10069 0x17c 0x408 0x678 0x01 0x02 0x17059 0x180 0x40c 0x67c 0x01 0x02 0x17059 0x184 0x410 0x680 0x01 0x02 0x17059 0x188 0x414 0x684 0x01 0x01 0x17059 0x18c 0x418 0x688 0x01 0x02 0x17059>;
					};

					usdhc2grp_8bit {
						fsl,pins = <0x178 0x404 0x670 0x01 0x02 0x10069 0x17c 0x408 0x678 0x01 0x02 0x17059 0x180 0x40c 0x67c 0x01 0x02 0x17059 0x184 0x410 0x680 0x01 0x02 0x17059 0x188 0x414 0x684 0x01 0x01 0x17059 0x18c 0x418 0x688 0x01 0x02 0x17059 0x190 0x41c 0x68c 0x01 0x01 0x17059 0x194 0x420 0x690 0x01 0x01 0x17059 0x198 0x424 0x694 0x01 0x01 0x17059 0x19c 0x428 0x698 0x01 0x01 0x17059>;
						linux,phandle = <0x2d>;
						phandle = <0x2d>;
					};

					usdhc2grp_8bit_100mhz {
						fsl,pins = <0x178 0x404 0x670 0x01 0x02 0x100b9 0x17c 0x408 0x678 0x01 0x02 0x170b9 0x180 0x40c 0x67c 0x01 0x02 0x170b9 0x184 0x410 0x680 0x01 0x02 0x170b9 0x188 0x414 0x684 0x01 0x01 0x170b9 0x18c 0x418 0x688 0x01 0x02 0x170b9 0x190 0x41c 0x68c 0x01 0x01 0x170b9 0x194 0x420 0x690 0x01 0x01 0x170b9 0x198 0x424 0x694 0x01 0x01 0x170b9 0x19c 0x428 0x698 0x01 0x01 0x170b9>;
						linux,phandle = <0x2e>;
						phandle = <0x2e>;
					};

					usdhc2grp_8bit_200mhz {
						fsl,pins = <0x178 0x404 0x670 0x01 0x02 0x100f9 0x17c 0x408 0x678 0x01 0x02 0x170f9 0x180 0x40c 0x67c 0x01 0x02 0x170f9 0x184 0x410 0x680 0x01 0x02 0x170f9 0x188 0x414 0x684 0x01 0x01 0x170f9 0x18c 0x418 0x688 0x01 0x02 0x170f9 0x190 0x41c 0x68c 0x01 0x01 0x170f9 0x194 0x420 0x690 0x01 0x01 0x170f9 0x198 0x424 0x694 0x01 0x01 0x170f9 0x19c 0x428 0x698 0x01 0x01 0x170f9>;
						linux,phandle = <0x2f>;
						phandle = <0x2f>;
					};

					wdoggrp {
						fsl,pins = <0x114 0x3a0 0x00 0x04 0x00 0x30b0>;
						linux,phandle = <0x17>;
						phandle = <0x17>;
					};

					ts_int_pin_mux {
						fsl,pins = <0x80 0x30c 0x00 0x05 0x00 0x79>;
						linux,phandle = <0x35>;
						phandle = <0x35>;
					};

					csi_pwn_rstgrp {
						fsl,pins = <0x64 0x2f0 0x00 0x05 0x00 0x10b0 0x6c 0x2f8 0x00 0x05 0x00 0x10b0>;
						linux,phandle = <0x33>;
						phandle = <0x33>;
					};
				};
			};

			iomuxc-gpr@020e4000 {
				compatible = "fsl,imx6ul-iomuxc-gpr\0fsl,imx6q-iomuxc-gpr\0syscon";
				reg = <0x20e4000 0x4000>;
				linux,phandle = <0x0b>;
				phandle = <0x0b>;
			};

			mqs {
				compatible = "fsl,imx6sx-mqs";
				gpr = <0x0b>;
				status = "disabled";
			};

			gpt@020e8000 {
				compatible = "fsl,imx6ul-gpt\0fsl,imx31-gpt";
				reg = <0x20e8000 0x4000>;
				interrupts = <0x00 0x6d 0x04>;
				clocks = <0x01 0x00 0x01 0x00>;
				clock-names = "ipg\0per";
			};

			sdma@020ec000 {
				compatible = "fsl,imx6ul-sdma\0fsl,imx35-sdma";
				reg = <0x20ec000 0x4000>;
				interrupts = <0x00 0x02 0x04>;
				clocks = <0x01 0xb8 0x01 0xb8>;
				clock-names = "ipg\0ahb";
				#dma-cells = <0x03>;
				iram = <0x22>;
				fsl,sdma-ram-script-name = "imx/sdma/sdma-imx6q.bin";
				linux,phandle = <0x07>;
				phandle = <0x07>;
			};

			pwm@020f0000 {
				compatible = "fsl,imx6ul-pwm\0fsl,imx27-pwm";
				reg = <0x20f0000 0x4000>;
				interrupts = <0x00 0x72 0x04>;
				clocks = <0x01 0x00 0x01 0x00>;
				clock-names = "ipg\0per";
				#pwm-cells = <0x02>;
			};

			pwm@020f4000 {
				compatible = "fsl,imx6ul-pwm\0fsl,imx27-pwm";
				reg = <0x20f4000 0x4000>;
				interrupts = <0x00 0x73 0x04>;
				clocks = <0x01 0x00 0x01 0x00>;
				clock-names = "ipg\0per";
				#pwm-cells = <0x02>;
			};

			pwm@020f8000 {
				compatible = "fsl,imx6ul-pwm\0fsl,imx27-pwm";
				reg = <0x20f8000 0x4000>;
				interrupts = <0x00 0x74 0x04>;
				clocks = <0x01 0x00 0x01 0x00>;
				clock-names = "ipg\0per";
				#pwm-cells = <0x02>;
			};

			pwm@020fc000 {
				compatible = "fsl,imx6ul-pwm\0fsl,imx27-pwm";
				reg = <0x20fc000 0x4000>;
				interrupts = <0x00 0x75 0x04>;
				clocks = <0x01 0x00 0x01 0x00>;
				clock-names = "ipg\0per";
				#pwm-cells = <0x02>;
			};
		};

		aips-bus@02100000 {
			compatible = "fsl,aips-bus\0simple-bus";
			#address-cells = <0x01>;
			#size-cells = <0x01>;
			reg = <0x2100000 0x100000>;
			ranges;

			usb@02184000 {
				compatible = "fsl,imx6ul-usb\0fsl,imx27-usb";
				reg = <0x2184000 0x200>;
				interrupts = <0x00 0x2b 0x04>;
				clocks = <0x01 0xcd>;
				fsl,usbphy = <0x23>;
				fsl,usbmisc = <0x24 0x00>;
				fsl,anatop = <0x1d>;
				ahb-burst-config = <0x00>;
				tx-burst-size-dword = <0x10>;
				rx-burst-size-dword = <0x10>;
				status = "okay";
				dr_mode = "otg";
				srp-disable;
				hnp-disable;
				adp-disable;
			};

			usb@02184200 {
				compatible = "fsl,imx6ul-usb\0fsl,imx27-usb";
				reg = <0x2184200 0x200>;
				interrupts = <0x00 0x2a 0x04>;
				clocks = <0x01 0xcd>;
				fsl,usbphy = <0x25>;
				fsl,usbmisc = <0x24 0x01>;
				ahb-burst-config = <0x00>;
				tx-burst-size-dword = <0x10>;
				rx-burst-size-dword = <0x10>;
				status = "okay";
				dr_mode = "host";
				disable-over-current;
			};

			usbmisc@02184800 {
				#index-cells = <0x01>;
				compatible = "fsl,imx6ul-usbmisc\0fsl,imx6q-usbmisc";
				reg = <0x2184800 0x200>;
				linux,phandle = <0x24>;
				phandle = <0x24>;
			};

			ethernet@02188000 {
				compatible = "fsl,imx6ul-fec\0fsl,imx6q-fec";
				reg = <0x2188000 0x4000>;
				interrupts = <0x00 0x76 0x04 0x00 0x77 0x04>;
				clocks = <0x01 0x90 0x01 0x91 0x01 0x30 0x01 0x2c 0x01 0x2c>;
				clock-names = "ipg\0ahb\0ptp\0enet_clk_ref\0enet_out";
				stop-mode = <0x0b 0x10 0x03>;
				fsl,num-tx-queues = <0x01>;
				fsl,num-rx-queues = <0x01>;
				fsl,magic-packet;
				fsl,wakeup_irq = <0x00>;
				status = "okay";
				pinctrl-names = "default";
				pinctrl-0 = <0x26 0x27>;
				phy-mode = "rmii";
				phy-handle = <0x28>;
				phy-reset-gpios = <0x16 0x07 0x01>;
				phy-reset-duration = <0xc8>;
			};

			usdhc@02190000 {
				compatible = "fsl,imx6ull-usdhc\0fsl,imx6sx-usdhc";
				reg = <0x2190000 0x4000>;
				interrupts = <0x00 0x16 0x04>;
				clocks = <0x01 0xce 0x01 0xce 0x01 0xce>;
				clock-names = "ipg\0ahb\0per";
				assigned-clocks = <0x01 0x40 0x01 0xce>;
				assigned-clock-parents = <0x01 0x26>;
				assigned-clock-rates = <0x00 0x7de2900>;
				bus-width = <0x04>;
				fsl,tuning-step = <0x02>;
				status = "okay";
				pinctrl-names = "default\0state_100mhz\0state_200mhz";
				pinctrl-0 = <0x29>;
				pinctrl-1 = <0x2a>;
				pinctrl-2 = <0x2b>;
				cd-gpios = <0x08 0x13 0x01>;
				keep-power-in-suspend;
				enable-sdio-wakeup;
				vmmc-supply = <0x2c>;
				no-1-8-v;
			};

			usdhc@02194000 {
				compatible = "fsl,imx6ull-usdhc\0fsl,imx6sx-usdhc";
				reg = <0x2194000 0x4000>;
				interrupts = <0x00 0x17 0x04>;
				clocks = <0x01 0xcf 0x01 0xcf 0x01 0xcf>;
				clock-names = "ipg\0ahb\0per";
				assigned-clocks = <0x01 0x41 0x01 0xcf>;
				assigned-clock-parents = <0x01 0x26>;
				assigned-clock-rates = <0x00 0x7de2900>;
				bus-width = <0x08>;
				fsl,tuning-step = <0x02>;
				status = "okay";
				pinctrl-names = "default\0state_100mhz\0state_200mhz";
				pinctrl-0 = <0x2d>;
				non-removable;
				no-1-8-v;
				pinctrl-1 = <0x2e>;
				pinctrl-2 = <0x2f>;
			};

			adc@02198000 {
				compatible = "fsl,imx6ul-adc\0fsl,vf610-adc";
				reg = <0x2198000 0x4000>;
				interrupts = <0x00 0x64 0x04>;
				clocks = <0x01 0x7b>;
				num-channels = <0x02>;
				clock-names = "adc";
				status = "disabled";
			};

			i2c@021a0000 {
				#address-cells = <0x01>;
				#size-cells = <0x00>;
				compatible = "fsl,imx6ul-i2c\0fsl,imx21-i2c";
				reg = <0x21a0000 0x4000>;
				interrupts = <0x00 0x24 0x04>;
				clocks = <0x01 0x9c>;
				status = "okay";
				clock-frequency = <0x186a0>;
				pinctrl-names = "default";
				pinctrl-0 = <0x30>;

				wm8960@1a {
					compatible = "wlf,wm8960";
					reg = <0x1a>;
					clocks = <0x01 0xb4>;
					clock-names = "mclk";
					wlf,shared-lrclk;
					linux,phandle = <0x4b>;
					phandle = <0x4b>;
				};

				mag3110@0e {
					compatible = "fsl,mag3110";
					reg = <0x0e>;
					position = <0x02>;
					status = "disabled";
				};

				ap3216c@1e {
					compatible = "ap3216c";
					reg = <0x1e>;
				};
			};

			i2c@021a4000 {
				#address-cells = <0x01>;
				#size-cells = <0x00>;
				compatible = "fsl,imx6ul-i2c\0fsl,imx21-i2c";
				reg = <0x21a4000 0x4000>;
				interrupts = <0x00 0x25 0x04>;
				clocks = <0x01 0x9d>;
				status = "okay";
				clock_frequency = <0x186a0>;
				pinctrl-names = "default";
				pinctrl-0 = <0x31>;

				wm8960@1a {
					compatible = "wlf,wm8960";
					reg = <0x1a>;
					clocks = <0x01 0xb4>;
					clock-names = "mclk";
					wlf,shared-lrclk;
					linux,phandle = <0x4c>;
					phandle = <0x4c>;
				};

				ov5640@3c {
					compatible = "ovti,ov5640";
					reg = <0x3c>;
					pinctrl-names = "default";
					pinctrl-0 = <0x32 0x33>;
					clocks = <0x01 0x8a>;
					clock-names = "csi_mclk";
					pwn-gpios = <0x08 0x04 0x01>;
					rst-gpios = <0x08 0x02 0x00>;
					csi_id = <0x00>;
					mclk = <0x16e3600>;
					mclk_source = <0x00>;
					status = "okay";

					port {

						endpoint {
							remote-endpoint = <0x34>;
							linux,phandle = <0x39>;
							phandle = <0x39>;
						};
					};
				};

				edt-ft5x06@38 {
					compatible = "edt,edt-ft5306\0edt,edt-ft5x06";
					pinctrl-names = "default";
					pinctrl-0 = <0x35 0x36>;
					reg = <0x38>;
					interrupt-parent = <0x08>;
					interrupts = <0x09 0x00>;
					reset-gpios = <0x16 0x09 0x01>;
					irq-gpios = <0x08 0x09 0x01>;
					status = "okay";
				};

				goodix_ts@5d {
					compatible = "goodix,gt9xx\0goodix,gt1151";
					reg = <0x5d>;
					status = "okay";
					interrupt-parent = <0x08>;
					interrupts = <0x09 0x00>;
					pinctrl-0 = <0x35 0x36>;
					goodix,rst-gpio = <0x16 0x09 0x01>;
					goodix,irq-gpio = <0x08 0x09 0x01>;
				};

				sii902x@39 {
					compatible = "SiI,sii902x";
					pinctrl-names = "default";
					pinctrl-0 = <0x37>;
					interrupt-parent = <0x08>;
					interrupts = <0x09 0x02>;
					mode_str = "1280x720M@60";
					bits-per-pixel = <0x10>;
					resets = <0x38>;
					reg = <0x39>;
					status = "disabled";
				};
			};

			i2c@021a8000 {
				#address-cells = <0x01>;
				#size-cells = <0x00>;
				compatible = "fsl,imx6ul-i2c\0fsl,imx21-i2c";
				reg = <0x21a8000 0x4000>;
				interrupts = <0x00 0x26 0x04>;
				clocks = <0x01 0x9e>;
				status = "disabled";
			};

			romcp@021ac000 {
				compatible = "fsl,imx6ul-romcp\0syscon";
				reg = <0x21ac000 0x4000>;
			};

			mmdc@021b0000 {
				compatible = "fsl,imx6ul-mmdc\0fsl,imx6q-mmdc";
				reg = <0x21b0000 0x4000>;
			};

			weim@021b8000 {
				compatible = "fsl,imx6ul-weim\0fsl,imx6q-weim";
				reg = <0x21b8000 0x4000>;
				interrupts = <0x00 0x0e 0x04>;
				clocks = <0x01 0x00>;
			};

			ocotp-ctrl@021bc000 {
				compatible = "fsl,imx6ull-ocotp\0syscon";
				reg = <0x21bc000 0x4000>;
				clocks = <0x01 0xa5>;
				linux,phandle = <0x1e>;
				phandle = <0x1e>;
			};

			csu@021c0000 {
				compatible = "fsl,imx6ul-csu";
				reg = <0x21c0000 0x4000>;
				interrupts = <0x00 0x15 0x04>;
				status = "disabled";
			};

			csi@021c4000 {
				compatible = "fsl,imx6ul-csi\0fsl,imx6s-csi";
				reg = <0x21c4000 0x4000>;
				interrupts = <0x00 0x07 0x04>;
				clocks = <0x01 0x00 0x01 0x8a 0x01 0x00>;
				clock-names = "disp-axi\0csi_mclk\0disp_dcic";
				status = "okay";

				port {

					endpoint {
						remote-endpoint = <0x39>;
						linux,phandle = <0x34>;
						phandle = <0x34>;
					};
				};
			};

			lcdif@021c8000 {
				compatible = "fsl,imx6ul-lcdif\0fsl,imx28-lcdif";
				reg = <0x21c8000 0x4000>;
				interrupts = <0x00 0x05 0x04>;
				clocks = <0x01 0xa2 0x01 0xa1 0x01 0x00>;
				clock-names = "pix\0axi\0disp_axi";
				status = "okay";
				pinctrl-names = "default";
				pinctrl-0 = <0x3a 0x3b>;
				display = <0x3c>;

				display {
					bits-per-pixel = <0x10>;
					bus-width = <0x18>;
					linux,phandle = <0x3c>;
					phandle = <0x3c>;

					display-timings {
						native-mode = <0x3d>;

						timing0 {
							clock-frequency = <0x30a32c0>;
							hactive = <0x400>;
							vactive = <0x258>;
							hfront-porch = <0xa0>;
							hback-porch = <0x8c>;
							hsync-len = <0x14>;
							vback-porch = <0x14>;
							vfront-porch = <0x0c>;
							vsync-len = <0x03>;
							hsync-active = <0x00>;
							vsync-active = <0x00>;
							de-active = <0x01>;
							pixelclk-active = <0x00>;
							linux,phandle = <0x3d>;
							phandle = <0x3d>;
						};
					};
				};
			};

			pxp@021cc000 {
				compatible = "fsl,imx6ull-pxp-dma\0fsl,imx7d-pxp-dma";
				reg = <0x21cc000 0x4000>;
				interrupts = <0x00 0x08 0x04 0x00 0x12 0x04>;
				clocks = <0x01 0x00 0x01 0xaf>;
				clock-names = "pxp_ipg\0pxp_axi";
				status = "okay";
			};

			qspi@021e0000 {
				#address-cells = <0x01>;
				#size-cells = <0x00>;
				compatible = "fsl,imx6ull-qspi\0fsl,imx6ul-qspi";
				reg = <0x21e0000 0x4000 0x60000000 0x10000000>;
				reg-names = "QuadSPI\0QuadSPI-memory";
				interrupts = <0x00 0x6b 0x04>;
				clocks = <0x01 0xb0 0x01 0xb0>;
				clock-names = "qspi_en\0qspi";
				status = "okay";
				pinctrl-names = "default";
				pinctrl-0 = <0x3e>;
				ddrsmp = <0x00>;

				n25q256a@0 {
					#address-cells = <0x01>;
					#size-cells = <0x01>;
					compatible = "micron,n25q256a";
					spi-max-frequency = <0x1ba8140>;
					spi-nor,ddr-quad-read-dummy = <0x06>;
					reg = <0x00>;
				};
			};

			serial@021e8000 {
				compatible = "fsl,imx6ul-uart\0fsl,imx6q-uart\0fsl,imx21-uart";
				reg = <0x21e8000 0x4000>;
				interrupts = <0x00 0x1b 0x04>;
				clocks = <0x01 0xbf 0x01 0xc0>;
				clock-names = "ipg\0per";
				dmas = <0x07 0x1b 0x04 0x00 0x07 0x1c 0x04 0x00>;
				dma-names = "rx\0tx";
				status = "disabled";
				pinctrl-names = "default";
				pinctrl-0 = <0x3f>;
				fsl,uart-has-rtscts;
			};

			serial@021ec000 {
				compatible = "fsl,imx6ul-uart\0fsl,imx6q-uart\0fsl,imx21-uart";
				reg = <0x21ec000 0x4000>;
				interrupts = <0x00 0x1c 0x04>;
				clocks = <0x01 0xc1 0x01 0xc2>;
				clock-names = "ipg\0per";
				dmas = <0x07 0x1d 0x04 0x00 0x07 0x1e 0x04 0x00>;
				dma-names = "rx\0tx";
				status = "okay";
				pinctrl-names = "default";
				pinctrl-0 = <0x40>;
			};

			serial@021f0000 {
				compatible = "fsl,imx6ul-uart\0fsl,imx6q-uart\0fsl,imx21-uart";
				reg = <0x21f0000 0x4000>;
				interrupts = <0x00 0x1d 0x04>;
				clocks = <0x01 0xc3 0x01 0xc4>;
				clock-names = "ipg\0per";
				dmas = <0x07 0x1f 0x04 0x00 0x07 0x20 0x04 0x00>;
				dma-names = "rx\0tx";
				status = "disabled";
			};

			serial@021f4000 {
				compatible = "fsl,imx6ul-uart\0fsl,imx6q-uart\0fsl,imx21-uart";
				reg = <0x21f4000 0x4000>;
				interrupts = <0x00 0x1e 0x04>;
				clocks = <0x01 0xc5 0x01 0xc6>;
				clock-names = "ipg\0per";
				dmas = <0x07 0x21 0x04 0x00 0x07 0x22 0x04 0x00>;
				dma-names = "rx\0tx";
				status = "disabled";
			};

			i2c@021f8000 {
				#address-cells = <0x01>;
				#size-cells = <0x00>;
				compatible = "fsl,imx6ul-i2c\0fsl,imx21-i2c";
				reg = <0x21f8000 0x4000>;
				interrupts = <0x00 0x23 0x04>;
				clocks = <0x01 0x9f>;
				status = "disabled";
			};

			serial@021fc000 {
				compatible = "fsl,imx6ul-uart\0fsl,imx6q-uart\0fsl,imx21-uart";
				reg = <0x21fc000 0x4000>;
				interrupts = <0x00 0x11 0x04>;
				clocks = <0x01 0xc7 0x01 0xc8>;
				clock-names = "ipg\0per";
				dmas = <0x07 0x00 0x04 0x00 0x07 0x2f 0x04 0x00>;
				dma-names = "rx\0tx";
				status = "disabled";
			};
		};

		aips-bus@02200000 {
			compatible = "fsl,aips-bus\0simple-bus";
			#address-cells = <0x01>;
			#size-cells = <0x01>;
			reg = <0x2200000 0x100000>;
			ranges;

			dcp@02280000 {
				compatible = "fsl,imx6sl-dcp";
				reg = <0x2280000 0x4000>;
				interrupts = <0x00 0x2e 0x04 0x00 0x2f 0x04 0x00 0x30 0x04>;
				clocks = <0x01 0xe6>;
				clock-names = "dcp";
			};

			rngb@02284000 {
				compatible = "fsl,imx6sl-rng\0fsl,imx-rng\0imx-rng";
				reg = <0x2284000 0x4000>;
				interrupts = <0x00 0x06 0x04>;
				clocks = <0x01 0x00>;
			};

			serial@02288000 {
				compatible = "fsl,imx6ul-uart\0fsl,imx6q-uart\0fsl,imx21-uart";
				reg = <0x2288000 0x4000>;
				interrupts = <0x00 0x28 0x04>;
				clocks = <0x01 0xcb 0x01 0xcc>;
				clock-names = "ipg\0per";
				dmas = <0x07 0x2d 0x04 0x00 0x07 0x2e 0x04 0x00>;
				dma-names = "rx\0tx";
				status = "disabled";
			};

			epdc@0228c000 {
				compatible = "fsl,imx7d-epdc";
				interrupts = <0x00 0x70 0x04>;
				reg = <0x228c000 0x4000>;
				clocks = <0x01 0xea 0x01 0xeb>;
				clock-names = "epdc_axi\0epdc_pix";
				status = "disabled";
			};

			iomuxc-snvs@02290000 {
				compatible = "fsl,imx6ull-iomuxc-snvs";
				reg = <0x2290000 0x10000>;
				pinctrl-names = "default_snvs";
				pinctrl-0 = <0x41>;

				imx6ul-evk {

					hoggrp-2 {
						fsl,pins = <0x08 0x4c 0x00 0x05 0x00 0x80000000>;
						linux,phandle = <0x41>;
						phandle = <0x41>;
					};

					dvfsgrp {
						fsl,pins = <0x14 0x58 0x00 0x05 0x00 0x79>;
						linux,phandle = <0x46>;
						phandle = <0x46>;
					};

					lcdifresetgrp {
						fsl,pins = <0x2c 0x70 0x00 0x05 0x00 0x79>;
					};

					spi4grp {
						fsl,pins = <0x00 0x44 0x00 0x05 0x00 0x70a1 0x04 0x48 0x00 0x05 0x00 0x70a1 0x24 0x68 0x00 0x05 0x00 0x70a1 0x28 0x6c 0x00 0x05 0x00 0x80000000>;
						linux,phandle = <0x4e>;
						phandle = <0x4e>;
					};

					fec1_resetgrp {
						fsl,pins = <0x24 0x68 0x00 0x05 0x00 0x79>;
						linux,phandle = <0x27>;
						phandle = <0x27>;
					};

					fec2_resetgrp {
						fsl,pins = <0x28 0x6c 0x00 0x05 0x00 0x79>;
						linux,phandle = <0x14>;
						phandle = <0x14>;
					};

					sai2_hp_det_grp {
						fsl,pins = <0x18 0x5c 0x00 0x05 0x00 0x17059>;
						linux,phandle = <0x0d>;
						phandle = <0x0d>;
					};

					ts_reset_pin_mux {
						fsl,pins = <0x2c 0x70 0x00 0x05 0x00 0x79>;
						linux,phandle = <0x36>;
						phandle = <0x36>;
					};

					beep {
						fsl,pins = <0x0c 0x50 0x00 0x05 0x00 0x17059>;
						linux,phandle = <0x48>;
						phandle = <0x48>;
					};
				};
			};

			snvs-gpr@0x02294000 {
				compatible = "fsl, imx6ull-snvs-gpr";
				reg = <0x2294000 0x10000>;
			};
		};
	};

	dht11 {
		compatible = "alientek, dht11";
		pinctrl-names = "default";
		pinctrl-0 = <0x42>;
		dht11-gpio = <0x08 0x01 0x01>;
		status = "okay";
	};

	ds18b20 {
		compatible = "alientek, ds18b20";
		pinctrl-names = "default";
		pinctrl-0 = <0x43>;
		ds18b20-gpio = <0x08 0x01 0x01>;
		status = "okay";
	};

	reserved-memory {
		#address-cells = <0x01>;
		#size-cells = <0x01>;
		ranges;

		linux,cma {
			compatible = "shared-dma-pool";
			reusable;
			size = <0x8000000>;
			linux,cma-default;
		};
	};

	backlight {
		compatible = "pwm-backlight";
		pwms = <0x44 0x00 0x4c4b40>;
		brightness-levels = <0x00 0x04 0x08 0x10 0x20 0x40 0x80 0xff>;
		default-brightness-level = <0x07>;
		status = "okay";
	};

	pxp_v4l2 {
		compatible = "fsl,imx6ul-pxp-v4l2\0fsl,imx6sx-pxp-v4l2\0fsl,imx6sl-pxp-v4l2";
		status = "okay";
	};

	regulators {
		compatible = "simple-bus";
		#address-cells = <0x01>;
		#size-cells = <0x00>;

		regulator@0 {
			compatible = "regulator-fixed";
			reg = <0x00>;
			regulator-name = "can-3v3";
			regulator-min-microvolt = <0x325aa0>;
			regulator-max-microvolt = <0x325aa0>;
			gpios = <0x45 0x03 0x01>;
			linux,phandle = <0x11>;
			phandle = <0x11>;
		};

		regulator@1 {
			compatible = "regulator-fixed";
			regulator-name = "VSD_3V3";
			regulator-min-microvolt = <0x325aa0>;
			regulator-max-microvolt = <0x325aa0>;
			enable-active-high;
			linux,phandle = <0x2c>;
			phandle = <0x2c>;
		};

		regulator-gpio {
			compatible = "regulator-gpio";
			pinctrl-names = "default";
			pinctrl-0 = <0x46>;
			regulator-min-microvolt = <0x13d620>;
			regulator-max-microvolt = <0x155cc0>;
			regulator-name = "gpio_dvfs";
			regulator-type = "voltage";
			gpios = <0x16 0x03 0x00>;
			states = <0x13d620 0x01 0x155cc0 0x00>;
			linux,phandle = <0x04>;
			phandle = <0x04>;
		};
	};

	leds {
		compatible = "gpio-leds";
		pinctrl-names = "default";
		pinctrl-0 = <0x47 0x48>;

		led1 {
			label = "sys-led";
			gpios = <0x08 0x03 0x01>;
			linux,default-trigger = "heartbeat";
			default-state = "on";
			status = "disabled";
		};

		beep {
			label = "beep";
			gpios = <0x16 0x01 0x01>;
			default-state = "off";
		};
	};

	gpio_keys@0 {
		compatible = "gpio-keys";
		pinctrl-names = "default";
		pinctrl-0 = <0x49>;
		#address-cells = <0x01>;
		#size-cells = <0x00>;
		autorepeat;

		key1@1 {
			label = "USER-KEY1";
			linux,code = <0x72>;
			gpios = <0x08 0x12 0x01>;
			gpio-key,wakeup;
		};
	};

	sound {
		compatible = "fsl,imx6ul-evk-wm8960\0fsl,imx-audio-wm8960";
		model = "wm8960-audio";
		cpu-dai = <0x4a>;
		audio-codec = <0x4b 0x4c>;
		asrc-controller = <0x4d>;
		codec-master;
		gpr = <0x0b 0x04 0x100000 0x100000>;
		hp-det = <0x03 0x00>;
		audio-routing = "Headphone Jack\0HP_L\0Headphone Jack\0HP_R\0Ext Spk\0SPK_LP\0Ext Spk\0SPK_LN\0Ext Spk\0SPK_RP\0Ext Spk\0SPK_RN\0LINPUT2\0Mic Jack\0LINPUT3\0Mic Jack\0RINPUT1\0Main MIC\0RINPUT2\0Main MIC\0Mic Jack\0MICB\0Main MIC\0MICB\0CPU-Playback\0ASRC-Playback\0Playback\0CPU-Playback\0ASRC-Capture\0CPU-Capture\0CPU-Capture\0Capture";
	};

	spi4 {
		compatible = "spi-gpio";
		pinctrl-names = "default";
		pinctrl-0 = <0x4e>;
		pinctrl-assert-gpios = <0x16 0x08 0x01>;
		status = "disabled";
		gpio-sck = <0x16 0x0b 0x00>;
		gpio-mosi = <0x16 0x0a 0x00>;
		cs-gpios = <0x16 0x07 0x00>;
		num-chipselects = <0x01>;
		#address-cells = <0x01>;
		#size-cells = <0x00>;

		gpio_spi@0 {
			compatible = "fairchild,74hc595";
			gpio-controller;
			#gpio-cells = <0x02>;
			reg = <0x00>;
			registers-number = <0x01>;
			registers-default = [57];
			spi-max-frequency = <0x186a0>;
			linux,phandle = <0x45>;
			phandle = <0x45>;
		};
	};

	sii902x-reset {
		compatible = "gpio-reset";
		reset-gpios = <0x16 0x09 0x01>;
		reset-delay-us = <0x186a0>;
		#reset-cells = <0x00>;
		status = "disabled";
		linux,phandle = <0x38>;
		phandle = <0x38>;
	};
	platform-probe-test {
		compatible = "training,imx6ull-platform-probe";
		led-gpios = <0x08 0x03 0x01>;
		status = "okay";
	};
};
